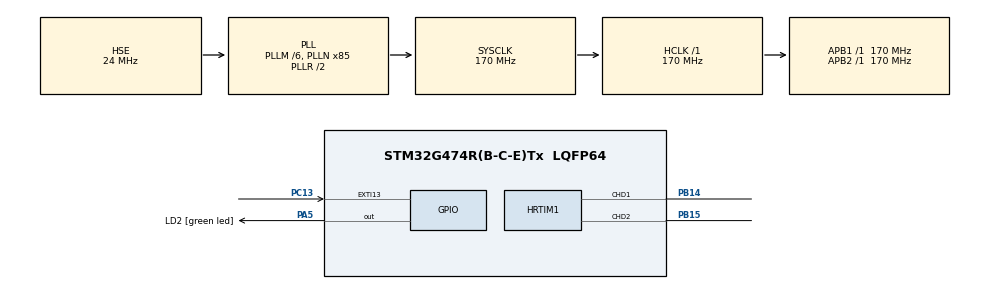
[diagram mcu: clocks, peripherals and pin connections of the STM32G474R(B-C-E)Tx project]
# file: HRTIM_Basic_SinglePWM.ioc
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HRTIM1.ADCTrigger_Id1=__NULL
HRTIM1.ADCTrigger_Id10=__NULL
HRTIM1.ADCTrigger_Id2=__NULL
HRTIM1.ADCTrigger_Id3=__NULL
HRTIM1.ADCTrigger_Id4=__NULL
HRTIM1.ADCTrigger_Id5=__NULL
HRTIM1.ADCTrigger_Id6=__NULL
HRTIM1.ADCTrigger_Id7=__NULL
HRTIM1.ADCTrigger_Id8=__NULL
HRTIM1.ADCTrigger_Id9=__NULL
HRTIM1.CompareUnit1-Output_TD1TD2=HRTIM_COMPAREUNIT_1
HRTIM1.Configuration_TD=Waveform
HRTIM1.Enable=HRTIM_BURSTMODECTL_DISABLED
HRTIM1.Event_EEV1=__NULL
HRTIM1.Event_EEV10=__NULL
HRTIM1.Event_EEV2=__NULL
HRTIM1.Event_EEV3=__NULL
HRTIM1.Event_EEV4=__NULL
HRTIM1.Event_EEV5=__NULL
HRTIM1.Event_EEV6=__NULL
HRTIM1.Event_EEV7=__NULL
HRTIM1.Event_EEV8=__NULL
HRTIM1.Event_EEV9=__NULL
HRTIM1.Fault_Line1=__NULL
HRTIM1.Fault_Line2=__NULL
HRTIM1.Fault_Line3=__NULL
HRTIM1.Fault_Line4=__NULL
HRTIM1.Fault_Line5=__NULL
HRTIM1.Fault_Line6=__NULL
HRTIM1.HRTIMInterruptResquests1=HRTIM_IT_NONE
HRTIM1.HRTIMInterruptResquests2=HRTIM_IT_NONE
HRTIM1.HRTIMInterruptResquests3=HRTIM_IT_NONE
HRTIM1.HRTIMInterruptResquests4=HRTIM_IT_NONE
HRTIM1.HRTIMInterruptResquests5=HRTIM_IT_NONE
HRTIM1.HRTIMInterruptResquests6=HRTIM_IT_NONE
HRTIM1.HRTIMInterruptResquests7=HRTIM_IT_NONE
HRTIM1.HRTIMInterruptResquests8=HRTIM_IT_NONE
HRTIM1.HRTIMInterruptResquests9=HRTIM_IT_NONE
HRTIM1.NumberDMARequests_TD=0
HRTIM1.NumberResetSource1-Output_TD1TD2=1
HRTIM1.NumberResetSource2_TD=1
HRTIM1.NumberSetSource1-Output_TD1TD2=1
HRTIM1.NumberSetSource2_TD=1
HRTIM1.Periode_TD=TIMD_PERIOD
HRTIM1.Polarity2-Output_TD1TD2=HRTIM_OUTPUTPOLARITY_LOW
HRTIM1.ResetOutput1_Source1-Output_TD1TD2=HRTIM_OUTPUTRESET_TIMCMP1
HRTIM1.ResetOutput2_Source1-Output_TD1TD2=HRTIM_OUTPUTRESET_TIMCMP1
HRTIM1.SetOutput1_Source1-Output_TD1TD2=HRTIM_OUTPUTSET_TIMPER
HRTIM1.SetOutput2_Source1-Output_TD1TD2=HRTIM_OUTPUTSET_TIMPER
HRTIM1.SyncOptions=HRTIM_SYNCOPTION_NONE
Mcu.Family=STM32G4
Mcu.Name=STM32G474R(B-C-E)Tx
Mcu.Package=LQFP64
Mcu.UserConstants=HRTIM_INPUT_CLOCK,170000000;TIMD_PWM_FREQ,100000;TIMD_DUTY_CYCLE,0.5
NVIC.EXTI15_10_IRQn=true\:0\:0\:false\:false\:true\:true\:true\:true
NVIC.PriorityGroup=NVIC_PRIORITYGROUP_4
PA13.Mode=Serial_Wire
PA13.Signal=SYS_JTMS-SWDIO
PA14.Mode=Serial_Wire
PA14.Signal=SYS_JTCK-SWCLK
PA5.GPIO_Label=LD2 [green led]
PA5.Signal=GPIO_Output
PB14.Mode=Output_TD1TD2
PB14.Signal=HRTIM1_CHD1
PB15.Mode=Output_TD1TD2
PB15.Signal=HRTIM1_CHD2
PB3.Signal=SYS_JTDO-SWO
PC13.GPIO_ModeDefaultEXTI=GPIO_MODE_IT_RISING
PC13.GPIO_PuPd=GPIO_NOPULL
PC13.Signal=GPXTI13
PC14-OSC32_IN.Signal=RCC_OSC32_IN
PC15-OSC32_OUT.Signal=RCC_OSC32_OUT
PC4.GPIO_ModeDefaultPP=GPIO_MODE_AF_PP
PC4.GPIO_PuPd=GPIO_NOPULL
PC4.GPIO_Speed=GPIO_SPEED_FREQ_LOW
PC4.Signal=USART1_TX
PC5.GPIO_ModeDefaultPP=GPIO_MODE_AF_PP
PC5.GPIO_PuPd=GPIO_NOPULL
PC5.GPIO_Speed=GPIO_SPEED_FREQ_LOW
PC5.Signal=USART1_RX
PF0-OSC_IN.Mode=HSE-External-Oscillator
PF0-OSC_IN.Signal=RCC_OSC_IN
PF1-OSC_OUT.Mode=HSE-External-Oscillator
PF1-OSC_OUT.Signal=RCC_OSC_OUT
ProjectManager.HeapSize=0x200
ProjectManager.StackSize=0x400
ProjectManager.TargetToolchain=STM32CubeIDE
RCC.ADC12Freq_Value=170000000
RCC.ADC345Freq_Value=170000000
RCC.AHBFreq_Value=170000000
RCC.APB1Freq_Value=170000000
RCC.APB1TimFreq_Value=170000000
RCC.APB2Freq_Value=170000000
RCC.APB2TimFreq_Value=170000000
RCC.CortexFreq_Value=170000000
RCC.EXTERNAL_CLOCK_VALUE=12288000
RCC.HCLKFreq_Value=170000000
RCC.HSE_VALUE=24000000
RCC.HSI48_VALUE=48000000
RCC.HSI_VALUE=16000000
RCC.LSE_VALUE=32768
RCC.PLLM=RCC_PLLM_DIV6
RCC.PLLN=85
RCC.PLLSourceVirtual=RCC_PLLSOURCE_HSE
RCC.SYSCLKFreq_VALUE=170000000
RCC.SYSCLKSource=RCC_SYSCLKSOURCE_PLLCLK
RCC.USBFreq_Value=170000000
RCC.VCOOutputFreq_Value=340000000
VP_SYS_VS_DBSignals.Mode=DisableDeadBatterySignals
board=NUCLEO-G474RE

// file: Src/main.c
/* USER CODE BEGIN Header */
/**
  ******************************************************************************
  * @file           : main.c
  * @brief          : Main program body
  ******************************************************************************
  * @attention
  *
  * Copyright (c) 2019 STMicroelectronics.
  * All rights reserved.
  *
  * This software is licensed under terms that can be found in the LICENSE file
  * in the root directory of this software component.
  * If no LICENSE file comes with this software, it is provided AS-IS.
  *
  ******************************************************************************
  */
/* USER CODE END Header */
#include "main.h"

/* USER CODE BEGIN Includes */
#include "stm32g4xx_nucleo.h"
/* USER CODE END Includes */

/* USER CODE BEGIN PD */

/* Formula below works for PWM frequency > 83kHz (with prescaler ratio = 1) */
#define TIMD_PERIOD ((uint16_t)((((uint64_t)HRTIM_INPUT_CLOCK) * 32) / TIMD_PWM_FREQ))

/* If the prescaler ratio is above 1 the formula must be changed as following
#define TIMD_PERIOD ((uint16_t)((((uint64_t)HRTIM_INPUT_CLOCK) * 16) / TIMD_PWM_FREQ))
#define TIMD_PERIOD ((uint16_t)((((uint64_t)HRTIM_INPUT_CLOCK) * 8) / TIMD_PWM_FREQ))
#define TIMD_PERIOD ((uint16_t)((((uint64_t)HRTIM_INPUT_CLOCK) * 4) / TIMD_PWM_FREQ))
#define TIMD_PERIOD ((uint16_t)((((uint64_t)HRTIM_INPUT_CLOCK) * 2) / TIMD_PWM_FREQ))
#define TIMD_PERIOD ((uint16_t)((((uint64_t)HRTIM_INPUT_CLOCK)) / TIMD_PWM_FREQ))
#define TIMD_PERIOD ((uint16_t)((((uint64_t)HRTIM_INPUT_CLOCK) / 2) / TIMD_PWM_FREQ))
#define TIMD_PERIOD ((uint16_t)((((uint64_t)HRTIM_INPUT_CLOCK) / 4) / TIMD_PWM_FREQ))
*/

/* USER CODE END PD */

HRTIM_HandleTypeDef hhrtim1;

/* USER CODE BEGIN PV */

uint32_t compare = 0;
//uint32_t duty_percent=80;
volatile uint32_t duty_percent = 80;

/* USER CODE END PV */

void SystemClock_Config(void);
static void MX_GPIO_Init(void);
static void MX_HRTIM1_Init(void);
/* USER CODE BEGIN PFP */
/* Private function prototypes -----------------------------------------------*/

/* USER CODE END PFP */

int main(void)
{

  /* MCU Configuration--------------------------------------------------------*/

  /* Reset of all peripherals, Initializes the Flash interface and the Systick. */
  HAL_Init();

  /* Configure the system clock */
  SystemClock_Config();

  /* Initialize all configured peripherals */
  MX_GPIO_Init();
  MX_HRTIM1_Init();
  /* USER CODE BEGIN 2 */

  /* LED2 toggles during the demo */
  BSP_LED_Init(LED2);

  /* Enable HRTIM's outputs TD1 and start Timer D */
  HAL_HRTIM_WaveformOutputStart(&hhrtim1, HRTIM_OUTPUT_TD1);
  HAL_HRTIM_WaveformOutputStart(&hhrtim1, HRTIM_OUTPUT_TD2);
  HAL_HRTIM_WaveformCounterStart(&hhrtim1, HRTIM_TIMERID_TIMER_D);

  /* USER CODE END 2 */

  /* Infinite loop */
  while (1)
  {

    /* USER CODE BEGIN 3 */

    BSP_LED_Toggle(LED2);
    HAL_Delay(1000);
    //    duty_percent=30;
    compare = (uint32_t)((duty_percent / 100.0f) * (float)TIMD_PERIOD);
    __HAL_HRTIM_SETCOMPARE(&hhrtim1, HRTIM_TIMERINDEX_TIMER_D, HRTIM_COMPAREUNIT_1, compare);
  }
  /* USER CODE END 3 */
}

void SystemClock_Config(void)
{
  RCC_OscInitTypeDef RCC_OscInitStruct = {0};
  RCC_ClkInitTypeDef RCC_ClkInitStruct = {0};

  /** Configure the main internal regulator output voltage
  */
  HAL_PWREx_ControlVoltageScaling(PWR_REGULATOR_VOLTAGE_SCALE1_BOOST);

  /** Initializes the RCC Oscillators according to the specified parameters
  * in the RCC_OscInitTypeDef structure.
  */
  RCC_OscInitStruct.OscillatorType = RCC_OSCILLATORTYPE_HSE;
  RCC_OscInitStruct.HSEState = RCC_HSE_ON;
  RCC_OscInitStruct.PLL.PLLState = RCC_PLL_ON;
  RCC_OscInitStruct.PLL.PLLSource = RCC_PLLSOURCE_HSE;
  RCC_OscInitStruct.PLL.PLLM = RCC_PLLM_DIV6;
  RCC_OscInitStruct.PLL.PLLN = 85;
  RCC_OscInitStruct.PLL.PLLP = RCC_PLLP_DIV2;
  RCC_OscInitStruct.PLL.PLLQ = RCC_PLLQ_DIV2;
  RCC_OscInitStruct.PLL.PLLR = RCC_PLLR_DIV2;
  if (HAL_RCC_OscConfig(&RCC_OscInitStruct) != HAL_OK)
  {
    Error_Handler();
  }

  /** Initializes the CPU, AHB and APB buses clocks
  */
  RCC_ClkInitStruct.ClockType = RCC_CLOCKTYPE_HCLK|RCC_CLOCKTYPE_SYSCLK
                              |RCC_CLOCKTYPE_PCLK1|RCC_CLOCKTYPE_PCLK2;
  RCC_ClkInitStruct.SYSCLKSource = RCC_SYSCLKSOURCE_PLLCLK;
  RCC_ClkInitStruct.AHBCLKDivider = RCC_SYSCLK_DIV1;
  RCC_ClkInitStruct.APB1CLKDivider = RCC_HCLK_DIV1;
  RCC_ClkInitStruct.APB2CLKDivider = RCC_HCLK_DIV1;

  if (HAL_RCC_ClockConfig(&RCC_ClkInitStruct, FLASH_LATENCY_4) != HAL_OK)
  {
    Error_Handler();
  }
}

static void MX_HRTIM1_Init(void)
{

  HRTIM_TimeBaseCfgTypeDef pTimeBaseCfg = {0};
  HRTIM_TimerCtlTypeDef pTimerCtl = {0};
  HRTIM_TimerCfgTypeDef pTimerCfg = {0};
  HRTIM_CompareCfgTypeDef pCompareCfg = {0};
  HRTIM_OutputCfgTypeDef pOutputCfg = {0};

  hhrtim1.Instance = HRTIM1;
  hhrtim1.Init.HRTIMInterruptResquests = HRTIM_IT_NONE;
  hhrtim1.Init.SyncOptions = HRTIM_SYNCOPTION_NONE;
  if (HAL_HRTIM_Init(&hhrtim1) != HAL_OK)
  {
    Error_Handler();
  }
  if (HAL_HRTIM_DLLCalibrationStart(&hhrtim1, HRTIM_CALIBRATIONRATE_3) != HAL_OK)
  {
    Error_Handler();
  }
  if (HAL_HRTIM_PollForDLLCalibration(&hhrtim1, 10) != HAL_OK)
  {
    Error_Handler();
  }
  pTimeBaseCfg.Period = TIMD_PERIOD;
  pTimeBaseCfg.RepetitionCounter = 0x00;
  pTimeBaseCfg.PrescalerRatio = HRTIM_PRESCALERRATIO_MUL32;
  pTimeBaseCfg.Mode = HRTIM_MODE_CONTINUOUS;
  if (HAL_HRTIM_TimeBaseConfig(&hhrtim1, HRTIM_TIMERINDEX_TIMER_D, &pTimeBaseCfg) != HAL_OK)
  {
    Error_Handler();
  }
  pTimerCtl.UpDownMode = HRTIM_TIMERUPDOWNMODE_UP;
  pTimerCtl.GreaterCMP1 = HRTIM_TIMERGTCMP1_EQUAL;
  pTimerCtl.DualChannelDacEnable = HRTIM_TIMER_DCDE_DISABLED;
  if (HAL_HRTIM_WaveformTimerControl(&hhrtim1, HRTIM_TIMERINDEX_TIMER_D, &pTimerCtl) != HAL_OK)
  {
    Error_Handler();
  }
  pTimerCfg.InterruptRequests = HRTIM_TIM_IT_NONE;
  pTimerCfg.DMARequests = HRTIM_TIM_DMA_NONE;
  pTimerCfg.DMASrcAddress = 0x0000;
  pTimerCfg.DMADstAddress = 0x0000;
  pTimerCfg.DMASize = 0x1;
  pTimerCfg.HalfModeEnable = HRTIM_HALFMODE_DISABLED;
  pTimerCfg.InterleavedMode = HRTIM_INTERLEAVED_MODE_DISABLED;
  pTimerCfg.StartOnSync = HRTIM_SYNCSTART_DISABLED;
  pTimerCfg.ResetOnSync = HRTIM_SYNCRESET_DISABLED;
  pTimerCfg.DACSynchro = HRTIM_DACSYNC_NONE;
  pTimerCfg.PreloadEnable = HRTIM_PRELOAD_DISABLED;
  pTimerCfg.UpdateGating = HRTIM_UPDATEGATING_INDEPENDENT;
  pTimerCfg.BurstMode = HRTIM_TIMERBURSTMODE_MAINTAINCLOCK;
  pTimerCfg.RepetitionUpdate = HRTIM_UPDATEONREPETITION_DISABLED;
  pTimerCfg.PushPull = HRTIM_TIMPUSHPULLMODE_DISABLED;
  pTimerCfg.FaultEnable = HRTIM_TIMFAULTENABLE_NONE;
  pTimerCfg.FaultLock = HRTIM_TIMFAULTLOCK_READWRITE;
  pTimerCfg.DeadTimeInsertion = HRTIM_TIMDEADTIMEINSERTION_DISABLED;
  pTimerCfg.DelayedProtectionMode = HRTIM_TIMER_D_E_DELAYEDPROTECTION_DISABLED;
  pTimerCfg.UpdateTrigger = HRTIM_TIMUPDATETRIGGER_NONE;
  pTimerCfg.ResetTrigger = HRTIM_TIMRESETTRIGGER_NONE;
  pTimerCfg.ResetUpdate = HRTIM_TIMUPDATEONRESET_DISABLED;
  pTimerCfg.ReSyncUpdate = HRTIM_TIMERESYNC_UPDATE_UNCONDITIONAL;
  if (HAL_HRTIM_WaveformTimerConfig(&hhrtim1, HRTIM_TIMERINDEX_TIMER_D, &pTimerCfg) != HAL_OK)
  {
    Error_Handler();
  }
  pCompareCfg.CompareValue = 0xFFDF;
  if (HAL_HRTIM_WaveformCompareConfig(&hhrtim1, HRTIM_TIMERINDEX_TIMER_D, HRTIM_COMPAREUNIT_1, &pCompareCfg) != HAL_OK)
  {
    Error_Handler();
  }
  pOutputCfg.Polarity = HRTIM_OUTPUTPOLARITY_HIGH;
  pOutputCfg.SetSource = HRTIM_OUTPUTSET_TIMPER;
  pOutputCfg.ResetSource = HRTIM_OUTPUTRESET_TIMCMP1;
  pOutputCfg.IdleMode = HRTIM_OUTPUTIDLEMODE_NONE;
  pOutputCfg.IdleLevel = HRTIM_OUTPUTIDLELEVEL_INACTIVE;
  pOutputCfg.FaultLevel = HRTIM_OUTPUTFAULTLEVEL_NONE;
  pOutputCfg.ChopperModeEnable = HRTIM_OUTPUTCHOPPERMODE_DISABLED;
  pOutputCfg.BurstModeEntryDelayed = HRTIM_OUTPUTBURSTMODEENTRY_REGULAR;
  if (HAL_HRTIM_WaveformOutputConfig(&hhrtim1, HRTIM_TIMERINDEX_TIMER_D, HRTIM_OUTPUT_TD1, &pOutputCfg) != HAL_OK)
  {
    Error_Handler();
  }
  pOutputCfg.Polarity = HRTIM_OUTPUTPOLARITY_LOW;
  if (HAL_HRTIM_WaveformOutputConfig(&hhrtim1, HRTIM_TIMERINDEX_TIMER_D, HRTIM_OUTPUT_TD2, &pOutputCfg) != HAL_OK)
  {
    Error_Handler();
  }
  HAL_HRTIM_MspPostInit(&hhrtim1);

}

static void MX_GPIO_Init(void)
{
  GPIO_InitTypeDef GPIO_InitStruct = {0};

  /* GPIO Ports Clock Enable */
  __HAL_RCC_GPIOC_CLK_ENABLE();
  __HAL_RCC_GPIOF_CLK_ENABLE();
  __HAL_RCC_GPIOA_CLK_ENABLE();
  __HAL_RCC_GPIOB_CLK_ENABLE();

  /*Configure GPIO pin Output Level */
  HAL_GPIO_WritePin(LD2_GPIO_Port, LD2_Pin, GPIO_PIN_RESET);

  /*Configure GPIO pin : PC13 */
  GPIO_InitStruct.Pin = GPIO_PIN_13;
  GPIO_InitStruct.Mode = GPIO_MODE_IT_RISING;
  GPIO_InitStruct.Pull = GPIO_NOPULL;
  HAL_GPIO_Init(GPIOC, &GPIO_InitStruct);

  /*Configure GPIO pin : LD2_Pin */
  GPIO_InitStruct.Pin = LD2_Pin;
  GPIO_InitStruct.Mode = GPIO_MODE_OUTPUT_PP;
  GPIO_InitStruct.Pull = GPIO_NOPULL;
  GPIO_InitStruct.Speed = GPIO_SPEED_FREQ_LOW;
  HAL_GPIO_Init(LD2_GPIO_Port, &GPIO_InitStruct);

  /*Configure GPIO pins : PC4 PC5 */
  GPIO_InitStruct.Pin = GPIO_PIN_4|GPIO_PIN_5;
  GPIO_InitStruct.Mode = GPIO_MODE_AF_PP;
  GPIO_InitStruct.Pull = GPIO_NOPULL;
  GPIO_InitStruct.Speed = GPIO_SPEED_FREQ_LOW;
  GPIO_InitStruct.Alternate = GPIO_AF7_USART1;
  HAL_GPIO_Init(GPIOC, &GPIO_InitStruct);

  /* EXTI interrupt init*/
  HAL_NVIC_SetPriority(EXTI15_10_IRQn, 0, 0);
  HAL_NVIC_EnableIRQ(EXTI15_10_IRQn);

}

void Error_Handler(void)
{
  /* USER CODE BEGIN Error_Handler_Debug */

  /* Turn LED2 (GREEN) on */
  BSP_LED_On(LED2);
  /* User can add his own implementation to report the HAL error return state */
  while(1)
  {
  }
  /* USER CODE END Error_Handler_Debug */
}
